# MSP430F5529 register map
Vendor: msp430gen; File version: VERGEN_IDEMPOTENT_OUTPUT
Registers are 8-bit, read-write, reset 0x0 unless marked. A register's access mark holds for its fields unless they carry their own. Offsets are from the block's base; [hi:lo] are bit positions; {n}, {i} and the like mark numbered series.

## DMA
Base 0x00000500
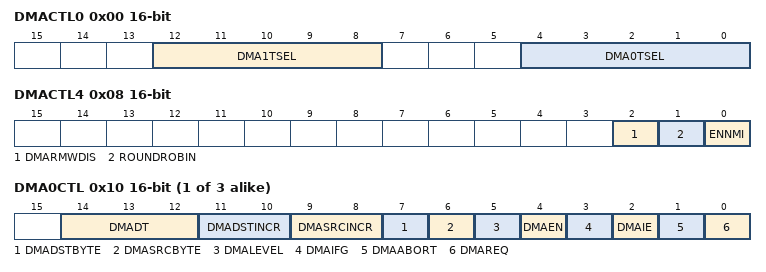
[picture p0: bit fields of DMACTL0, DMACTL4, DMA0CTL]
0x00 DMACTL0 16-bit — DMA Module Control 0
  [12:8] DMA1TSEL — DMA channel 1 transfer select bit 0
    0=DMA channel 1 transfer select 0: DMA_REQ (sw); 1=DMA channel 1 transfer select 1: Timer0_A (TA0CCR0.IFG); 2=DMA channel 1 transfer select 2: Timer0_A (TA0CCR2.IFG); 3=DMA channel 1 transfer select 3: Timer1_A (TA1CCR0.IFG); 4=DMA channel 1 transfer select 4: Timer1_A (TA1CCR2.IFG); 5=DMA channel 1 transfer select 5: Timer2_A (TA2CCR0.IFG); 6=DMA channel 1 transfer select 6: Timer2_A (TA2CCR2.IFG); 7=DMA channel 1 transfer select 7: TimerB (TB0CCR0.IFG); 8=DMA channel 1 transfer select 8: TimerB (TB0CCR2.IFG); {v}=DMA channel 1 transfer select {v}: Reserved (v=9..15); 16=DMA channel 1 transfer select 16: USCIA0 receive; 17=DMA channel 1 transfer select 17: USCIA0 transmit; 18=DMA channel 1 transfer select 18: USCIB0 receive; 19=DMA channel 1 transfer select 19: USCIB0 transmit; 20=DMA channel 1 transfer select 20: USCIA1 receive; 21=DMA channel 1 transfer select 21: USCIA1 transmit; 22=DMA channel 1 transfer select 22: USCIB1 receive; 23=DMA channel 1 transfer select 23: USCIB1 transmit; 24=DMA channel 1 transfer select 24: ADC12IFGx; 25=DMA channel 1 transfer select 25: Reserved; 26=DMA channel 1 transfer select 26: Reserved; 27=DMA channel 1 transfer select 27: USB FNRXD; 28=DMA channel 1 transfer select 28: USB ready; 29=DMA channel 1 transfer select 29: Multiplier ready; 30=DMA channel 1 transfer select 30: previous DMA channel DMA0IFG; 31=DMA channel 1 transfer select 31: ext. Trigger (DMAE0)
  [4:0] DMA0TSEL — DMA channel 0 transfer select bit 0
    0=DMA channel 0 transfer select 0: DMA_REQ (sw); 1=DMA channel 0 transfer select 1: Timer0_A (TA0CCR0.IFG); 2=DMA channel 0 transfer select 2: Timer0_A (TA0CCR2.IFG); 3=DMA channel 0 transfer select 3: Timer1_A (TA1CCR0.IFG); 4=DMA channel 0 transfer select 4: Timer1_A (TA1CCR2.IFG); 5=DMA channel 0 transfer select 5: Timer2_A (TA2CCR0.IFG); 6=DMA channel 0 transfer select 6: Timer2_A (TA2CCR2.IFG); 7=DMA channel 0 transfer select 7: TimerB (TB0CCR0.IFG); 8=DMA channel 0 transfer select 8: TimerB (TB0CCR2.IFG); {v}=DMA channel 0 transfer select {v}: Reserved (v=9..15); 16=DMA channel 0 transfer select 16: USCIA0 receive; 17=DMA channel 0 transfer select 17: USCIA0 transmit; 18=DMA channel 0 transfer select 18: USCIB0 receive; 19=DMA channel 0 transfer select 19: USCIB0 transmit; 20=DMA channel 0 transfer select 20: USCIA1 receive; 21=DMA channel 0 transfer select 21: USCIA1 transmit; 22=DMA channel 0 transfer select 22: USCIB1 receive; 23=DMA channel 0 transfer select 23: USCIB1 transmit; 24=DMA channel 0 transfer select 24: ADC12IFGx; 25=DMA channel 0 transfer select 25: Reserved; 26=DMA channel 0 transfer select 26: Reserved; 27=DMA channel 0 transfer select 27: USB FNRXD; 28=DMA channel 0 transfer select 28: USB ready; 29=DMA channel 0 transfer select 29: Multiplier ready; 30=DMA channel 0 transfer select 30: previous DMA channel DMA2IFG; 31=DMA channel 0 transfer select 31: ext. Trigger (DMAE0)
0x02 DMACTL1 16-bit — DMA Module Control 1
  [4:0] DMA2TSEL — DMA channel 2 transfer select bit 0
    0=DMA channel 2 transfer select 0: DMA_REQ (sw); 1=DMA channel 2 transfer select 1: Timer0_A (TA0CCR0.IFG); 2=DMA channel 2 transfer select 2: Timer0_A (TA0CCR2.IFG); 3=DMA channel 2 transfer select 3: Timer1_A (TA1CCR0.IFG); 4=DMA channel 2 transfer select 4: Timer1_A (TA1CCR2.IFG); 5=DMA channel 2 transfer select 5: Timer2_A (TA2CCR0.IFG); 6=DMA channel 2 transfer select 6: Timer2_A (TA2CCR2.IFG); 7=DMA channel 2 transfer select 7: TimerB (TB0CCR0.IFG); 8=DMA channel 2 transfer select 8: TimerB (TB0CCR2.IFG); {v}=DMA channel 2 transfer select {v}: Reserved (v=9..15); 16=DMA channel 2 transfer select 16: USCIA0 receive; 17=DMA channel 2 transfer select 17: USCIA0 transmit; 18=DMA channel 2 transfer select 18: USCIB0 receive; 19=DMA channel 2 transfer select 19: USCIB0 transmit; 20=DMA channel 2 transfer select 20: USCIA1 receive; 21=DMA channel 2 transfer select 21: USCIA1 transmit; 22=DMA channel 2 transfer select 22: USCIB1 receive; 23=DMA channel 2 transfer select 23: USCIB1 transmit; 24=DMA channel 2 transfer select 24: ADC12IFGx; 25=DMA channel 2 transfer select 25: Reserved; 26=DMA channel 2 transfer select 26: Reserved; 27=DMA channel 2 transfer select 27: USB FNRXD; 28=DMA channel 2 transfer select 28: USB ready; 29=DMA channel 2 transfer select 29: Multiplier ready; 30=DMA channel 2 transfer select 30: previous DMA channel DMA1IFG; 31=DMA channel 2 transfer select 31: ext. Trigger (DMAE0)
0x04 DMACTL2 16-bit — DMA Module Control 2
0x06 DMACTL3 16-bit — DMA Module Control 3
0x08 DMACTL4 16-bit — DMA Module Control 4
  [2] DMARMWDIS — Inhibited DMA transfers during read-modify-write CPU operations
  [1] ROUNDROBIN — Round-Robin DMA channel priorities
  [0] ENNMI — Enable NMI interruption of DMA
0x0E DMAIV 16-bit — DMA Interrupt Vector Word
{0x10+0x10*i} DMA{i}CTL 16-bit (i=0..2) — DMA Channel {i} Control
  [14:12] DMADT — DMA transfer mode bit 0
    0=DMA transfer mode 0: Single transfer; 1=DMA transfer mode 1: Block transfer; 2=DMA transfer mode 2: Burst-Block transfer; 3=DMA transfer mode 3: Burst-Block transfer; 4=DMA transfer mode 4: Repeated Single transfer; 5=DMA transfer mode 5: Repeated Block transfer; 6=DMA transfer mode 6: Repeated Burst-Block transfer; 7=DMA transfer mode 7: Repeated Burst-Block transfer
  [11:10] DMADSTINCR — DMA destination increment bit 0
    0=DMA destination increment 0: destination address unchanged; 1=DMA destination increment 1: destination address unchanged; 2=DMA destination increment 2: destination address decremented; 3=DMA destination increment 3: destination address incremented
  [9:8] DMASRCINCR — DMA source increment bit 0
    0=DMA source increment 0: source address unchanged; 1=DMA source increment 1: source address unchanged; 2=DMA source increment 2: source address decremented; 3=DMA source increment 3: source address incremented
  [7] DMADSTBYTE — DMA destination byte
  [6] DMASRCBYTE — DMA source byte
  [5] DMALEVEL — DMA level sensitive trigger select
  [4] DMAEN — DMA enable
  [3] DMAIFG — DMA interrupt flag
  [2] DMAIE — DMA interrupt enable
  [1] DMAABORT — DMA transfer aborted by NMI
  [0] DMAREQ — Initiate DMA transfer with DMATSEL
{0x12+0x10*i} DMA{i}SA 32-bit (i=0..2) — DMA Channel {i} Source Address
{0x16+0x10*i} DMA{i}DA 32-bit (i=0..2) — DMA Channel {i} Destination Address
{0x1A+0x10*i} DMA{i}SZ 16-bit (i=0..2) — DMA Channel {i} Transfer Size
